# G32R502 register map
Vendor: Geehy Semiconductor Co., Ltd.; Series: G32R5; File version: 1.0
CPU: CM52 r0p1, little endian, MPU, FPU, DSP, VTOR, 4 interrupt priority bits
Registers are 32-bit, read-write, reset 0x0 unless marked. A register's access mark holds for its fields unless they carry their own. Offsets are from the block's base; [hi:lo] are bit positions; {n}, {i} and the like mark numbered series.

## WDT — Watchdog Timer
Base 0x40010000
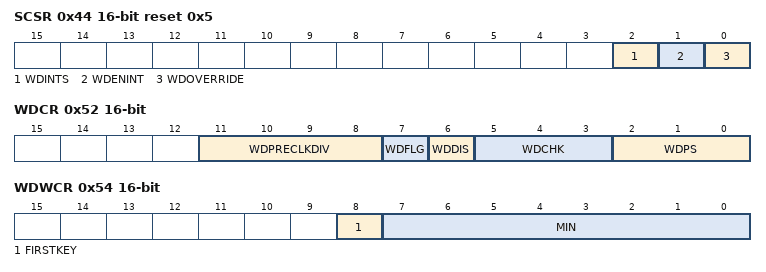
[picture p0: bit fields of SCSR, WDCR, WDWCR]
0x44 SCSR 16-bit access per field reset 0x5 — System Control & Status Register
  [2] WDINTS ro — Watchdog Interrupt Status
  [1] WDENINT rw — Watchdog Interrupt Enable/Reset Disable
  [0] WDOVERRIDE rw — Watchdog Enable Lock
0x46 WDCNTR 16-bit ro — Watchdog Counter Register
  [7:0] WDCNTR — Watchdog Counter
0x4A WDKEY 16-bit — Watchdog Reset Key Register
  [7:0] WDKEY — Watchdog Counter Reset
0x52 WDCR 16-bit — Watchdog Control Register
  [11:8] WDPRECLKDIV — Watchdog Clock Pre-divider
  [7] WDFLG — Watchdog reset status flag bit
  [6] WDDIS — Watchdog Disable
  [5:3] WDCHK — Watchdog Check Bits
  [2:0] WDPS — Watchdog Clock Prescaler
0x54 WDWCR 16-bit access per field — Watchdog Windowed Control Register
  [8] FIRSTKEY ro — First valid WDKEY detected
  [7:0] MIN rw — Watchdog Window Threshold

## SPEC — SPEC_REGS
Base 0x40012C00
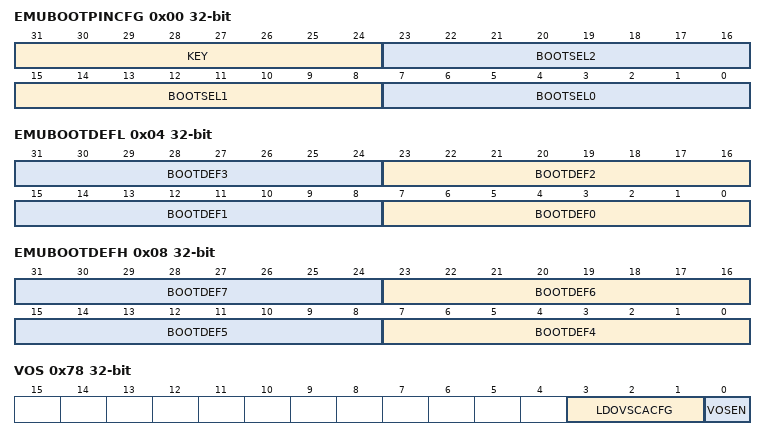
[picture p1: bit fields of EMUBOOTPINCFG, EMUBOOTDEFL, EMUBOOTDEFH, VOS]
0x00 EMUBOOTPINCFG — Emulation Boot pin configuration register
  [31:24] KEY — Key Word
  [23:16] BOOTSEL2 — Boot Mode Select Pin 2
  [15:8] BOOTSEL1 — Boot Mode Select Pin 1
  [7:0] BOOTSEL0 — Boot Mode Select Pin 0
0x04 EMUBOOTDEFL — Emulation Boot definition low register
  [8n+7:8n] BOOTDEF{n} (n=0..3) — BOOT_DEF{n} Mode/Options
0x08 EMUBOOTDEFH — Emulation Boot definition high register
  [8n-25:8n-32] BOOTDEF{n} (n=4..7) — BOOT_DEF{n} Mode/Options
0x64 CFGSMSSEL reset 0x8 — CFGSMS static configuration selection register
  [3:0] CFGSMSSEL — CFGSMS Static configuration Select
0x74 APBCLKDIVCFG reset 0x3 — APB clock divider control register
  [4:0] APBCLKDIVCFG — APB clock divide configure
0x78 VOS — LDO voltage scaling control register
  [3:1] LDOVSCACFG — LDO voltage scaling configure
  [0] VOSEN — VOS Enable

## DMA_CHSEL — DMA Channel Trigger Source Select
Base 0x40013000
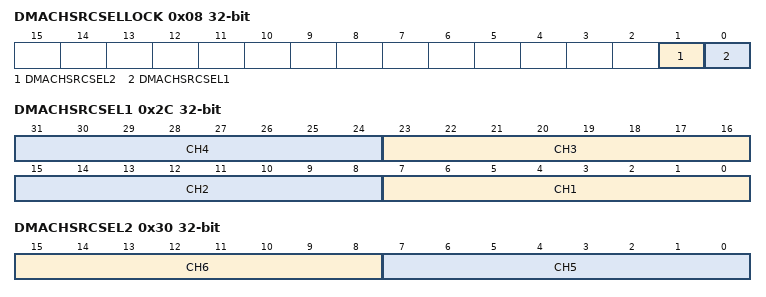
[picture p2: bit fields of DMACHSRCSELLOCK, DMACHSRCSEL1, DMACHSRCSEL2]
0x08 DMACHSRCSELLOCK — DMA Channel Triger Source Select Lock Register
  [1] DMACHSRCSEL2 — DMACHSRCSEL2 Register Lock bit
  [0] DMACHSRCSEL1 — DMACHSRCSEL1 Register Lock bit
0x2C DMACHSRCSEL1 — DMA Channel Trigger Source Select Register-1
  [8n-1:8n-8] CH{n} (n=1..4) — Selects the Trigger and Sync Source CH{n} of DMA
0x30 DMACHSRCSEL2 — DMA Channel Trigger Source Select Register-2
  [15:8] CH6 — Selects the Trigger and Sync Source CH6 of DMA
  [7:0] CH5 — Selects the Trigger and Sync Source CH5 of DMA

## CLK — CLK_REGS
Base 0x40013400
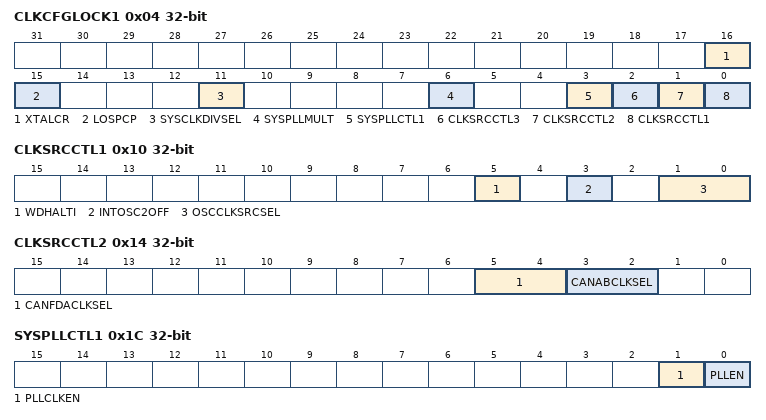
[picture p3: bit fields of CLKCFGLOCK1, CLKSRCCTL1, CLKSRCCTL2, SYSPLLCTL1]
0x04 CLKCFGLOCK1 — Lock bit for CLKCFG registers
  [16] XTALCR — Lock bit for XTALCR register
  [15] LOSPCP — Lock bit for LOSPCP register
  [11] SYSCLKDIVSEL — Lock bit for SYSCLKDIVSEL register
  [6] SYSPLLMULT — Lock bit for SYSPLLMULT register
  [3] SYSPLLCTL1 — Lock bit for SYSPLLCTL1 register
  [2] CLKSRCCTL3 — Lock bit for CLKSRCCTL3 register
  [1] CLKSRCCTL2 — Lock bit for CLKSRCCTL2 register
  [0] CLKSRCCTL1 — Lock bit for CLKSRCCTL1 register
0x10 CLKSRCCTL1 — Clock Source Control register-1
  [5] WDHALTI — Watchdog HALT Mode Ignore Bit
  [3] INTOSC2OFF — Internal Oscillator 2 Off Bit
  [1:0] OSCCLKSRCSEL — Oscillator Clock Source Select Bit
0x14 CLKSRCCTL2 — Clock Source Control register-2
  [5:4] CANFDACLKSEL — CANFDA Bit-Clock Source Select Bit
  [3:2] CANABCLKSEL — CANA Bit-Clock Source Select Bit
0x18 CLKSRCCTL3 — Clock Source Control register-3
  [2:0] XCLKOUTSEL — XCLKOUT Source Select Bit
0x1C SYSPLLCTL1 — SYSPLL Control register-1
  [1] PLLCLKEN — SYSPLL bypassed or included in the PLLSYSCLK path
  [0] PLLEN — SYSPLL enabled or disabled
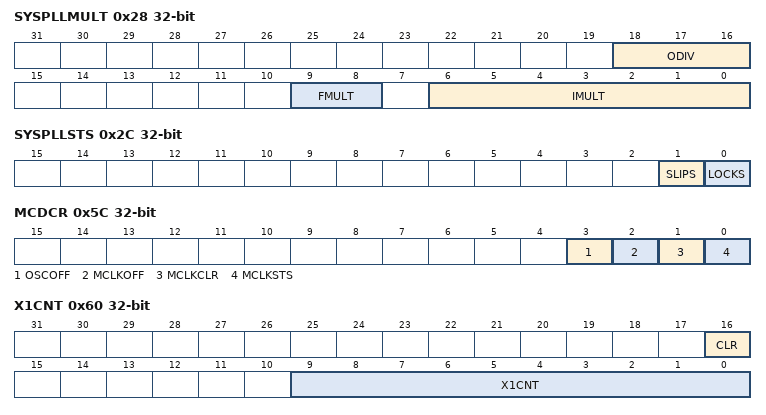
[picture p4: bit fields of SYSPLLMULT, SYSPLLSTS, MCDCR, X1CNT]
0x28 SYSPLLMULT — SYSPLL Multiplier register
  [18:16] ODIV — SYSPLL Output Clock Divider
  [9:8] FMULT — SYSPLL Fractional Multiplier
  [6:0] IMULT — SYSPLL Integer Multiplier
0x2C SYSPLLSTS ro — SYSPLL Status register Go
  [1] SLIPS — SYSPLL Slip Status Bit
  [0] LOCKS — SYSPLL Lock Status Bit
0x44 SYSCLKDIVSEL reset 0x2 — System Clock Divider Select register
  [5:0] PLLSYSCLKDIV — PLLSYSCLK Divide Select
0x50 XCLKOUTDIVSEL reset 0x3 — XCLKOUT Divider Select register
  [1:0] XCLKOUTDIV — XCLKOUT Divide Select
0x58 LOSPCP reset 0x2 — Low Speed Clock Source Prescalar
  [2:0] LSPCLKDIV — These bits configure the low-speed peripheral clock (LSPCLK) rate
0x5C MCDCR access per field — Missing Clock Detect Control Register
  [3] OSCOFF rw — Oscillator Clock Disconnect from MCD Bit
  [2] MCLKOFF rw — Missing Clock Detect Off Bit
  [1] MCLKCLR rw — Missing Clock Clear Bit
  [0] MCLKSTS ro — Missing Clock Status Bit
0x60 X1CNT access per field — 10-bit Counter on X1 Clock
  [16] CLR rw — X1 Counter clear
  [9:0] X1CNT ro — X1 Counter
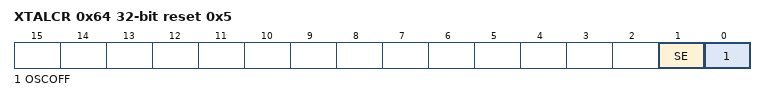
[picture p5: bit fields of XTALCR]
0x64 XTALCR reset 0x5 — XTAL Control Register
  [1] SE — XTAL Oscilator in Single-Ended mode
  [0] OSCOFF — XTAL Oscillator powered-down
